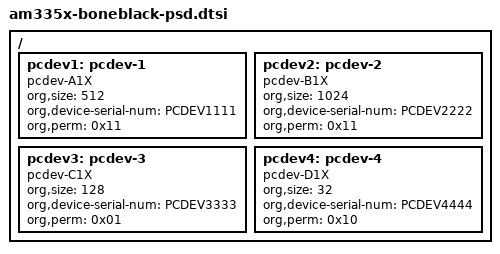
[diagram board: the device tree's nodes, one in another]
/ {
    pcdev1: pcdev-1 {
        compatible = "pcdev-A1X"; 
        org,size = <512>; 
        org,device-serial-num = "PCDEV1111";
        org,perm = <0x11>;
    };

    pcdev2: pcdev-2 {
        compatible = "pcdev-B1X";
        org,size = <1024>;
        org,device-serial-num = "PCDEV2222";
        org,perm = <0x11>;
    };

    pcdev3: pcdev-3 {
        compatible = "pcdev-C1X";
        org,size = <128>;
        org,device-serial-num = "PCDEV3333";
        org,perm = <0x01>;
    };

    pcdev4: pcdev-4 {
        compatible = "pcdev-D1X";
        org,size = <32>;
        org,device-serial-num = "PCDEV4444";
        org,perm = <0x10>;
    };
};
